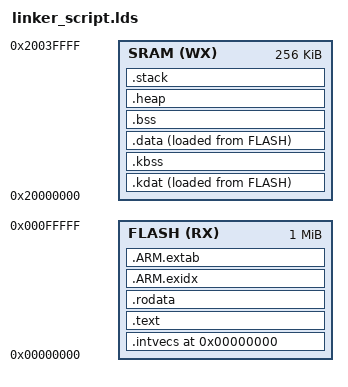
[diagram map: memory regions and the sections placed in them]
INCLUDE param.lds

// use this linker script for creating final hex
// provide correct FLASH and SRAM size based on your target MCU
MEMORY
{
    FLASH (RX) : ORIGIN = 0x00000000, LENGTH = 0x00100000
    SRAM (WX)  : ORIGIN = 0x20000000, LENGTH = 0x00040000
}

REGION_ALIAS("REGION_TEXT", FLASH);
REGION_ALIAS("REGION_BSS", SRAM);
REGION_ALIAS("REGION_DATA", SRAM);
REGION_ALIAS("REGION_STACK", SRAM);
REGION_ALIAS("REGION_HEAP", SRAM);
REGION_ALIAS("REGION_ARM_EXIDX", FLASH);
REGION_ALIAS("REGION_ARM_EXTAB", FLASH);

ENTRY("skibios_boot")

SECTIONS {

    PROVIDE (_intvecs_base_address = 0x0);

    .intvecs (_intvecs_base_address) : AT (_intvecs_base_address) {
        KEEP (*(.intvecs))
    } > REGION_TEXT
    
    .kdat (_kernel_base_address) : ALIGN(0x4){
        __kdat_load__ = LOADADDR(.kdat);
        __kdat_start__ = .;
        KEEP(*(.kdat))
        KEEP(*(.kdat*))
        __kdat_end__ = .;
        . = ALIGN(0x4);

    } > REGION_DATA AT> REGION_TEXT

    .kbss : {
        __kbss_start__ = .;
        *(.kbss);
        __kbss_end__ = .;
    } > REGION_BSS


    .text : {
        CREATE_OBJECT_SYMBOLS
        *(.text)
        *(.text.*)
        . = ALIGN(0x4);
        KEEP (*(.ctors))
        . = ALIGN(0x4);
        KEEP (*(.dtors))
        . = ALIGN(0x4);
        __init_array_start = .;
        KEEP (*(.init_array*))
        __init_array_end = .;
        *(.init)
        *(.fini*)
    } > REGION_TEXT

    PROVIDE (__etext = .);
    PROVIDE (_etext = .);
    PROVIDE (etext = .);

    .rodata : {
        *(.rodata)
        *(.rodata*)
    } > REGION_TEXT

    .data (_app_base_address): ALIGN (4) {
        __data_load__ = LOADADDR (.data);
        __data_start__ = .;
        *(.data)
        *(.data*)
        . = ALIGN (4);
        __data_end__ = .;
    } > REGION_DATA AT> REGION_TEXT

    .ARM.exidx : {
        __exidx_start = .;
        *(.ARM.exidx* .gnu.linkonce.armexidx.*)
        __exidx_end = .;
    } > REGION_ARM_EXIDX

    .ARM.extab : {
        *(.ARM.extab* .gnu.linkonce.armextab.*)
    } > REGION_ARM_EXTAB

    .bss : {
        __bss_start__ = .;
        *(.shbss)
        *(.bss)
        *(.bss.*)
        *(COMMON)
        . = ALIGN (4);
        __bss_end__ = .;
    } > REGION_BSS

    .heap : {
        __heap_start__ = .;
        end = __heap_start__;
    } > REGION_HEAP

    .stack : ALIGN(0x8) {
        _stack = .;
        __stack = .;
        KEEP(*(.stack))
    } > REGION_STACK

    /DISCARD/ :
    {
        libc.a ( * )
        libm.a ( * )
        libgcc.a ( * )
    }

}
